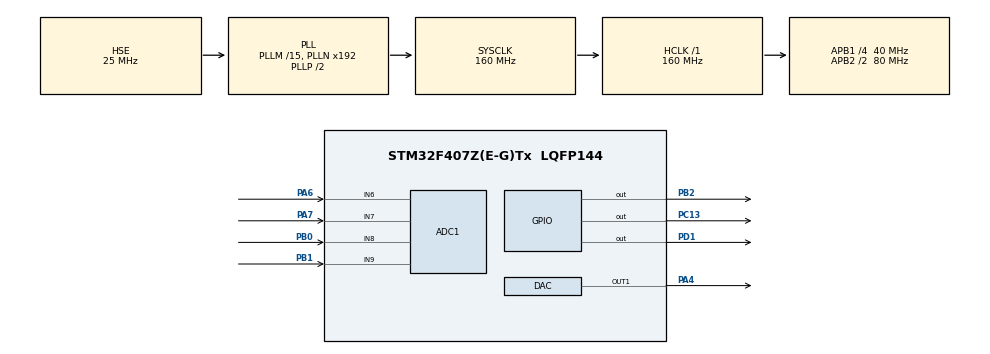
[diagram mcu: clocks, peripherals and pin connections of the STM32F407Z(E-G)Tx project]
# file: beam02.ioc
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ADC1.Channel-4\#ChannelRegularConversion=ADC_CHANNEL_6
ADC1.Channel-5\#ChannelRegularConversion=ADC_CHANNEL_7
ADC1.Channel-6\#ChannelRegularConversion=ADC_CHANNEL_8
ADC1.Channel-7\#ChannelRegularConversion=ADC_CHANNEL_9
ADC1.ContinuousConvMode=DISABLE
ADC1.DMAContinuousRequests=ENABLE
ADC1.EOCSelection=ADC_EOC_SEQ_CONV
ADC1.ExternalTrigConv=ADC_EXTERNALTRIGCONV_T8_TRGO
ADC1.NbrOfConversion=4
ADC1.NbrOfConversionFlag=1
ADC1.Rank-4\#ChannelRegularConversion=1
ADC1.Rank-5\#ChannelRegularConversion=2
ADC1.Rank-6\#ChannelRegularConversion=3
ADC1.Rank-7\#ChannelRegularConversion=4
ADC1.SamplingTime-4\#ChannelRegularConversion=ADC_SAMPLETIME_15CYCLES
ADC1.SamplingTime-5\#ChannelRegularConversion=ADC_SAMPLETIME_15CYCLES
ADC1.SamplingTime-6\#ChannelRegularConversion=ADC_SAMPLETIME_15CYCLES
ADC1.SamplingTime-7\#ChannelRegularConversion=ADC_SAMPLETIME_15CYCLES
ADC1.ScanConvMode=ENABLE
ADC1.master=1
Dma.ADC1.0.Direction=DMA_PERIPH_TO_MEMORY
Dma.ADC1.0.FIFOMode=DMA_FIFOMODE_DISABLE
Dma.ADC1.0.Instance=DMA2_Stream0
Dma.ADC1.0.MemDataAlignment=DMA_MDATAALIGN_WORD
Dma.ADC1.0.MemInc=DMA_MINC_ENABLE
Dma.ADC1.0.Mode=DMA_CIRCULAR
Dma.ADC1.0.PeriphDataAlignment=DMA_PDATAALIGN_WORD
Dma.ADC1.0.PeriphInc=DMA_PINC_DISABLE
Dma.ADC1.0.Priority=DMA_PRIORITY_LOW
Dma.DAC1.2.Direction=DMA_MEMORY_TO_PERIPH
Dma.DAC1.2.FIFOMode=DMA_FIFOMODE_DISABLE
Dma.DAC1.2.Instance=DMA1_Stream5
Dma.DAC1.2.MemDataAlignment=DMA_MDATAALIGN_WORD
Dma.DAC1.2.MemInc=DMA_MINC_ENABLE
Dma.DAC1.2.Mode=DMA_CIRCULAR
Dma.DAC1.2.PeriphDataAlignment=DMA_PDATAALIGN_WORD
Dma.DAC1.2.PeriphInc=DMA_PINC_DISABLE
Dma.DAC1.2.Priority=DMA_PRIORITY_LOW
Dma.Request0=ADC1
Dma.Request1=TIM6_UP
Dma.Request2=DAC1
Dma.TIM6_UP.1.Direction=DMA_PERIPH_TO_MEMORY
Dma.TIM6_UP.1.FIFOMode=DMA_FIFOMODE_DISABLE
Dma.TIM6_UP.1.Instance=DMA1_Stream1
Dma.TIM6_UP.1.MemDataAlignment=DMA_MDATAALIGN_WORD
Dma.TIM6_UP.1.MemInc=DMA_MINC_ENABLE
Dma.TIM6_UP.1.Mode=DMA_CIRCULAR
Dma.TIM6_UP.1.PeriphDataAlignment=DMA_PDATAALIGN_WORD
Dma.TIM6_UP.1.PeriphInc=DMA_PINC_DISABLE
Dma.TIM6_UP.1.Priority=DMA_PRIORITY_LOW
Mcu.Family=STM32F4
Mcu.Name=STM32F407Z(E-G)Tx
Mcu.Package=LQFP144
NVIC.ADC_IRQn=true\:0\:0\:false\:false\:true\:true\:true\:true
NVIC.DMA1_Stream1_IRQn=true\:0\:0\:false\:false\:true\:false\:true\:true
NVIC.DMA1_Stream5_IRQn=true\:0\:0\:false\:false\:true\:false\:true\:true
NVIC.DMA2_Stream0_IRQn=true\:0\:0\:false\:false\:true\:false\:true\:true
NVIC.PriorityGroup=NVIC_PRIORITYGROUP_4
NVIC.TIM6_DAC_IRQn=true\:0\:0\:false\:false\:true\:true\:true\:true
PA13.Mode=Trace_Asynchronous_SW
PA13.Signal=SYS_JTMS-SWDIO
PA14.Mode=Trace_Asynchronous_SW
PA14.Signal=SYS_JTCK-SWCLK
PA4.Signal=COMP_DAC1_group
PA6.Signal=ADCx_IN6
PA7.Signal=ADCx_IN7
PB0.Signal=ADCx_IN8
PB1.Signal=ADCx_IN9
PB2.Signal=GPIO_Output
PB3.Mode=Trace_Asynchronous_SW
PB3.Signal=SYS_JTDO-SWO
PC13-ANTI_TAMP.Signal=GPIO_Output
PD1.Signal=GPIO_Output
PH0-OSC_IN.Mode=HSE-External-Oscillator
PH0-OSC_IN.Signal=RCC_OSC_IN
PH1-OSC_OUT.Mode=HSE-External-Oscillator
PH1-OSC_OUT.Signal=RCC_OSC_OUT
ProjectManager.HeapSize=0x200
ProjectManager.StackSize=0x400
ProjectManager.TargetToolchain=STM32CubeIDE
RCC.48MHZClocksFreq_Value=80000000
RCC.AHBFreq_Value=160000000
RCC.APB1CLKDivider=RCC_HCLK_DIV4
RCC.APB1Freq_Value=40000000
RCC.APB1TimFreq_Value=80000000
RCC.APB2CLKDivider=RCC_HCLK_DIV2
RCC.APB2Freq_Value=80000000
RCC.APB2TimFreq_Value=160000000
RCC.CortexFreq_Value=160000000
RCC.HCLKFreq_Value=160000000
RCC.HSE_VALUE=25000000
RCC.HSI_VALUE=16000000
RCC.LSE_VALUE=32768
RCC.PLLM=15
RCC.PLLSourceVirtual=RCC_PLLSOURCE_HSE
RCC.SYSCLKFreq_VALUE=160000000
RCC.SYSCLKSource=RCC_SYSCLKSOURCE_PLLCLK
RCC.VCOOutputFreq_Value=320000000
SH.ADCx_IN6.0=ADC1_IN6,IN6
SH.ADCx_IN7.0=ADC1_IN7,IN7
SH.ADCx_IN8.0=ADC1_IN8,IN8
SH.ADCx_IN9.0=ADC1_IN9,IN9
SH.COMP_DAC1_group.0=DAC_OUT1,DAC_OUT1
TIM2.Channel-Output\ Compare1\ No\ Output=TIM_CHANNEL_1
TIM2.Channel-Output\ Compare3\ No\ Output=TIM_CHANNEL_3
TIM2.Channel-Output\ Compare4\ No\ Output=TIM_CHANNEL_4
TIM2.Channel-PWM\ Generation2\ No\ Output=TIM_CHANNEL_2
TIM6.Period=24
TIM6.Prescaler=19
TIM6.TIM_MasterOutputTrigger=TIM_TRGO_UPDATE
TIM8.AutoReloadPreload=TIM_AUTORELOAD_PRELOAD_DISABLE
TIM8.Period=24
TIM8.Prescaler=19
TIM8.RepetitionCounter=0
TIM8.TIM_MasterOutputTrigger=TIM_TRGO_UPDATE
VP_TIM1_VS_ClockSourceINT.Mode=Internal
VP_TIM2_VS_no_output1.Mode=Output Compare1 No Output
VP_TIM2_VS_no_output2.Mode=PWM Generation2 No Output
VP_TIM2_VS_no_output3.Mode=Output Compare3 No Output
VP_TIM2_VS_no_output4.Mode=Output Compare4 No Output
VP_TIM6_VS_ClockSourceINT.Mode=Enable_Timer
VP_TIM8_VS_ClockSourceINT.Mode=Internal
board=custom

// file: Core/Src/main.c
/* USER CODE BEGIN Header */
/**
  ******************************************************************************
  * @file           : main.c
  * @brief          : Main program body
  ******************************************************************************
  * @attention
  *
  * Copyright (c) 2025 STMicroelectronics.
  * All rights reserved.
  *
  * This software is licensed under terms that can be found in the LICENSE file
  * in the root directory of this software component.
  * If no LICENSE file comes with this software, it is provided AS-IS.
  *
  ******************************************************************************
  */
/* USER CODE END Header */
#include "main.h"

ADC_HandleTypeDef hadc1;
DMA_HandleTypeDef hdma_adc1;

DAC_HandleTypeDef hdac;
DMA_HandleTypeDef hdma_dac1;

TIM_HandleTypeDef htim1;
TIM_HandleTypeDef htim2;
TIM_HandleTypeDef htim6;
TIM_HandleTypeDef htim8;
DMA_HandleTypeDef hdma_tim6_up;

/* USER CODE BEGIN PV */

extern void pgm_loop();
extern void pgm_init();

long int acc = 33;

void HAL_ADC_ConvCpltCallback1(ADC_HandleTypeDef* hadc)
{
    // Conversion Complete & DMA Transfer Complete As Well
    // So The AD_RES_BUFFER Is Now Updated & Let's Move Values To The PWM CCRx
    // Update The PWM Channels With Latest ADC Scan Conversion Results
	/*
    TIM2->CCR1 = (AD_RES_BUFFER[0] << 4);  // ADC CH6 -> PWM CH1
    TIM2->CCR2 = (AD_RES_BUFFER[1] << 4);  // ADC CH7 -> PWM CH2
    TIM2->CCR3 = (AD_RES_BUFFER[2] << 4);  // ADC CH8 -> PWM CH3
    TIM2->CCR4 = (AD_RES_BUFFER[3] << 4);  // ADC CH9 -> PWM CH4
    */
    acc ++;
}

/* USER CODE END PV */

void SystemClock_Config(void);
static void MX_GPIO_Init(void);
static void MX_DMA_Init(void);
static void MX_ADC1_Init(void);
static void MX_TIM2_Init(void);
static void MX_DAC_Init(void);
static void MX_TIM6_Init(void);
static void MX_TIM8_Init(void);
static void MX_TIM1_Init(void);

int main(void)
{

  /* MCU Configuration--------------------------------------------------------*/

  /* Reset of all peripherals, Initializes the Flash interface and the Systick. */
  HAL_Init();

  /* Configure the system clock */
  SystemClock_Config();

  /* Initialize all configured peripherals */
  MX_GPIO_Init();
  MX_DMA_Init();
  MX_ADC1_Init();
  MX_TIM2_Init();
  MX_DAC_Init();
  MX_TIM6_Init();
  MX_TIM8_Init();
  MX_TIM1_Init();
  /* USER CODE BEGIN 2 */

  pgm_init();

  /* USER CODE END 2 */

  /* Infinite loop */
  /* USER CODE BEGIN WHILE */

  while (1)
  {
	  pgm_loop();
    /* USER CODE END WHILE */

  }
}

void SystemClock_Config(void)
{
  RCC_OscInitTypeDef RCC_OscInitStruct = {0};
  RCC_ClkInitTypeDef RCC_ClkInitStruct = {0};

  /** Configure the main internal regulator output voltage
  */
  __HAL_RCC_PWR_CLK_ENABLE();
  __HAL_PWR_VOLTAGESCALING_CONFIG(PWR_REGULATOR_VOLTAGE_SCALE1);

  /** Initializes the RCC Oscillators according to the specified parameters
  * in the RCC_OscInitTypeDef structure.
  */
  RCC_OscInitStruct.OscillatorType = RCC_OSCILLATORTYPE_HSE;
  RCC_OscInitStruct.HSEState = RCC_HSE_ON;
  RCC_OscInitStruct.PLL.PLLState = RCC_PLL_ON;
  RCC_OscInitStruct.PLL.PLLSource = RCC_PLLSOURCE_HSE;
  RCC_OscInitStruct.PLL.PLLM = 15;
  RCC_OscInitStruct.PLL.PLLN = 192;
  RCC_OscInitStruct.PLL.PLLP = RCC_PLLP_DIV2;
  RCC_OscInitStruct.PLL.PLLQ = 4;
  if (HAL_RCC_OscConfig(&RCC_OscInitStruct) != HAL_OK)
  {
    Error_Handler();
  }

  /** Initializes the CPU, AHB and APB buses clocks
  */
  RCC_ClkInitStruct.ClockType = RCC_CLOCKTYPE_HCLK|RCC_CLOCKTYPE_SYSCLK
                              |RCC_CLOCKTYPE_PCLK1|RCC_CLOCKTYPE_PCLK2;
  RCC_ClkInitStruct.SYSCLKSource = RCC_SYSCLKSOURCE_PLLCLK;
  RCC_ClkInitStruct.AHBCLKDivider = RCC_SYSCLK_DIV1;
  RCC_ClkInitStruct.APB1CLKDivider = RCC_HCLK_DIV4;
  RCC_ClkInitStruct.APB2CLKDivider = RCC_HCLK_DIV2;

  if (HAL_RCC_ClockConfig(&RCC_ClkInitStruct, FLASH_LATENCY_5) != HAL_OK)
  {
    Error_Handler();
  }
}

static void MX_ADC1_Init(void)
{

  ADC_ChannelConfTypeDef sConfig = {0};

  /** Configure the global features of the ADC (Clock, Resolution, Data Alignment and number of conversion)
  */
  hadc1.Instance = ADC1;
  hadc1.Init.ClockPrescaler = ADC_CLOCK_SYNC_PCLK_DIV4;
  hadc1.Init.Resolution = ADC_RESOLUTION_12B;
  hadc1.Init.ScanConvMode = ENABLE;
  hadc1.Init.ContinuousConvMode = DISABLE;
  hadc1.Init.DiscontinuousConvMode = DISABLE;
  hadc1.Init.ExternalTrigConvEdge = ADC_EXTERNALTRIGCONVEDGE_RISING;
  hadc1.Init.ExternalTrigConv = ADC_EXTERNALTRIGCONV_T8_TRGO;
  hadc1.Init.DataAlign = ADC_DATAALIGN_RIGHT;
  hadc1.Init.NbrOfConversion = 4;
  hadc1.Init.DMAContinuousRequests = ENABLE;
  hadc1.Init.EOCSelection = ADC_EOC_SEQ_CONV;
  if (HAL_ADC_Init(&hadc1) != HAL_OK)
  {
    Error_Handler();
  }

  /** Configure for the selected ADC regular channel its corresponding rank in the sequencer and its sample time.
  */
  sConfig.Channel = ADC_CHANNEL_6;
  sConfig.Rank = 1;
  sConfig.SamplingTime = ADC_SAMPLETIME_15CYCLES;
  if (HAL_ADC_ConfigChannel(&hadc1, &sConfig) != HAL_OK)
  {
    Error_Handler();
  }

  /** Configure for the selected ADC regular channel its corresponding rank in the sequencer and its sample time.
  */
  sConfig.Channel = ADC_CHANNEL_7;
  sConfig.Rank = 2;
  if (HAL_ADC_ConfigChannel(&hadc1, &sConfig) != HAL_OK)
  {
    Error_Handler();
  }

  /** Configure for the selected ADC regular channel its corresponding rank in the sequencer and its sample time.
  */
  sConfig.Channel = ADC_CHANNEL_8;
  sConfig.Rank = 3;
  if (HAL_ADC_ConfigChannel(&hadc1, &sConfig) != HAL_OK)
  {
    Error_Handler();
  }

  /** Configure for the selected ADC regular channel its corresponding rank in the sequencer and its sample time.
  */
  sConfig.Channel = ADC_CHANNEL_9;
  sConfig.Rank = 4;
  if (HAL_ADC_ConfigChannel(&hadc1, &sConfig) != HAL_OK)
  {
    Error_Handler();
  }

}

static void MX_DAC_Init(void)
{

  DAC_ChannelConfTypeDef sConfig = {0};

  /** DAC Initialization
  */
  hdac.Instance = DAC;
  if (HAL_DAC_Init(&hdac) != HAL_OK)
  {
    Error_Handler();
  }

  /** DAC channel OUT1 config
  */
  sConfig.DAC_Trigger = DAC_TRIGGER_NONE;
  sConfig.DAC_OutputBuffer = DAC_OUTPUTBUFFER_ENABLE;
  if (HAL_DAC_ConfigChannel(&hdac, &sConfig, DAC_CHANNEL_1) != HAL_OK)
  {
    Error_Handler();
  }

}

static void MX_TIM1_Init(void)
{

  TIM_ClockConfigTypeDef sClockSourceConfig = {0};
  TIM_MasterConfigTypeDef sMasterConfig = {0};

  htim1.Instance = TIM1;
  htim1.Init.Prescaler = 0;
  htim1.Init.CounterMode = TIM_COUNTERMODE_UP;
  htim1.Init.Period = 65535;
  htim1.Init.ClockDivision = TIM_CLOCKDIVISION_DIV1;
  htim1.Init.RepetitionCounter = 0;
  htim1.Init.AutoReloadPreload = TIM_AUTORELOAD_PRELOAD_DISABLE;
  if (HAL_TIM_Base_Init(&htim1) != HAL_OK)
  {
    Error_Handler();
  }
  sClockSourceConfig.ClockSource = TIM_CLOCKSOURCE_INTERNAL;
  if (HAL_TIM_ConfigClockSource(&htim1, &sClockSourceConfig) != HAL_OK)
  {
    Error_Handler();
  }
  sMasterConfig.MasterOutputTrigger = TIM_TRGO_RESET;
  sMasterConfig.MasterSlaveMode = TIM_MASTERSLAVEMODE_DISABLE;
  if (HAL_TIMEx_MasterConfigSynchronization(&htim1, &sMasterConfig) != HAL_OK)
  {
    Error_Handler();
  }

}

static void MX_TIM2_Init(void)
{

  TIM_MasterConfigTypeDef sMasterConfig = {0};
  TIM_OC_InitTypeDef sConfigOC = {0};

  htim2.Instance = TIM2;
  htim2.Init.Prescaler = 0;
  htim2.Init.CounterMode = TIM_COUNTERMODE_UP;
  htim2.Init.Period = 4294967295;
  htim2.Init.ClockDivision = TIM_CLOCKDIVISION_DIV1;
  htim2.Init.AutoReloadPreload = TIM_AUTORELOAD_PRELOAD_DISABLE;
  if (HAL_TIM_OC_Init(&htim2) != HAL_OK)
  {
    Error_Handler();
  }
  if (HAL_TIM_PWM_Init(&htim2) != HAL_OK)
  {
    Error_Handler();
  }
  sMasterConfig.MasterOutputTrigger = TIM_TRGO_RESET;
  sMasterConfig.MasterSlaveMode = TIM_MASTERSLAVEMODE_DISABLE;
  if (HAL_TIMEx_MasterConfigSynchronization(&htim2, &sMasterConfig) != HAL_OK)
  {
    Error_Handler();
  }
  sConfigOC.OCMode = TIM_OCMODE_TIMING;
  sConfigOC.Pulse = 0;
  sConfigOC.OCPolarity = TIM_OCPOLARITY_HIGH;
  sConfigOC.OCFastMode = TIM_OCFAST_DISABLE;
  if (HAL_TIM_OC_ConfigChannel(&htim2, &sConfigOC, TIM_CHANNEL_1) != HAL_OK)
  {
    Error_Handler();
  }
  sConfigOC.OCMode = TIM_OCMODE_PWM1;
  if (HAL_TIM_PWM_ConfigChannel(&htim2, &sConfigOC, TIM_CHANNEL_2) != HAL_OK)
  {
    Error_Handler();
  }
  sConfigOC.OCMode = TIM_OCMODE_TIMING;
  if (HAL_TIM_OC_ConfigChannel(&htim2, &sConfigOC, TIM_CHANNEL_3) != HAL_OK)
  {
    Error_Handler();
  }
  if (HAL_TIM_OC_ConfigChannel(&htim2, &sConfigOC, TIM_CHANNEL_4) != HAL_OK)
  {
    Error_Handler();
  }

}

static void MX_TIM6_Init(void)
{

  TIM_MasterConfigTypeDef sMasterConfig = {0};

  htim6.Instance = TIM6;
  htim6.Init.Prescaler = 19;
  htim6.Init.CounterMode = TIM_COUNTERMODE_UP;
  htim6.Init.Period = 24;
  htim6.Init.AutoReloadPreload = TIM_AUTORELOAD_PRELOAD_DISABLE;
  if (HAL_TIM_Base_Init(&htim6) != HAL_OK)
  {
    Error_Handler();
  }
  sMasterConfig.MasterOutputTrigger = TIM_TRGO_UPDATE;
  sMasterConfig.MasterSlaveMode = TIM_MASTERSLAVEMODE_DISABLE;
  if (HAL_TIMEx_MasterConfigSynchronization(&htim6, &sMasterConfig) != HAL_OK)
  {
    Error_Handler();
  }

}

static void MX_TIM8_Init(void)
{

  TIM_ClockConfigTypeDef sClockSourceConfig = {0};
  TIM_MasterConfigTypeDef sMasterConfig = {0};

  htim8.Instance = TIM8;
  htim8.Init.Prescaler = 19;
  htim8.Init.CounterMode = TIM_COUNTERMODE_UP;
  htim8.Init.Period = 24;
  htim8.Init.ClockDivision = TIM_CLOCKDIVISION_DIV1;
  htim8.Init.RepetitionCounter = 0;
  htim8.Init.AutoReloadPreload = TIM_AUTORELOAD_PRELOAD_DISABLE;
  if (HAL_TIM_Base_Init(&htim8) != HAL_OK)
  {
    Error_Handler();
  }
  sClockSourceConfig.ClockSource = TIM_CLOCKSOURCE_INTERNAL;
  if (HAL_TIM_ConfigClockSource(&htim8, &sClockSourceConfig) != HAL_OK)
  {
    Error_Handler();
  }
  sMasterConfig.MasterOutputTrigger = TIM_TRGO_UPDATE;
  sMasterConfig.MasterSlaveMode = TIM_MASTERSLAVEMODE_DISABLE;
  if (HAL_TIMEx_MasterConfigSynchronization(&htim8, &sMasterConfig) != HAL_OK)
  {
    Error_Handler();
  }

}

static void MX_DMA_Init(void)
{

  /* DMA controller clock enable */
  __HAL_RCC_DMA2_CLK_ENABLE();
  __HAL_RCC_DMA1_CLK_ENABLE();

  /* DMA interrupt init */
  /* DMA1_Stream1_IRQn interrupt configuration */
  HAL_NVIC_SetPriority(DMA1_Stream1_IRQn, 0, 0);
  HAL_NVIC_EnableIRQ(DMA1_Stream1_IRQn);
  /* DMA1_Stream5_IRQn interrupt configuration */
  HAL_NVIC_SetPriority(DMA1_Stream5_IRQn, 0, 0);
  HAL_NVIC_EnableIRQ(DMA1_Stream5_IRQn);
  /* DMA2_Stream0_IRQn interrupt configuration */
  HAL_NVIC_SetPriority(DMA2_Stream0_IRQn, 0, 0);
  HAL_NVIC_EnableIRQ(DMA2_Stream0_IRQn);

}

static void MX_GPIO_Init(void)
{
  GPIO_InitTypeDef GPIO_InitStruct = {0};

  /* GPIO Ports Clock Enable */
  __HAL_RCC_GPIOC_CLK_ENABLE();
  __HAL_RCC_GPIOH_CLK_ENABLE();
  __HAL_RCC_GPIOA_CLK_ENABLE();
  __HAL_RCC_GPIOB_CLK_ENABLE();
  __HAL_RCC_GPIOD_CLK_ENABLE();

  /*Configure GPIO pin Output Level */
  HAL_GPIO_WritePin(GPIOC, GPIO_PIN_13, GPIO_PIN_RESET);

  /*Configure GPIO pin Output Level */
  HAL_GPIO_WritePin(GPIOB, GPIO_PIN_2, GPIO_PIN_RESET);

  /*Configure GPIO pin Output Level */
  HAL_GPIO_WritePin(GPIOD, GPIO_PIN_1, GPIO_PIN_RESET);

  /*Configure GPIO pin : PC13 */
  GPIO_InitStruct.Pin = GPIO_PIN_13;
  GPIO_InitStruct.Mode = GPIO_MODE_OUTPUT_PP;
  GPIO_InitStruct.Pull = GPIO_NOPULL;
  GPIO_InitStruct.Speed = GPIO_SPEED_FREQ_LOW;
  HAL_GPIO_Init(GPIOC, &GPIO_InitStruct);

  /*Configure GPIO pin : PB2 */
  GPIO_InitStruct.Pin = GPIO_PIN_2;
  GPIO_InitStruct.Mode = GPIO_MODE_OUTPUT_PP;
  GPIO_InitStruct.Pull = GPIO_NOPULL;
  GPIO_InitStruct.Speed = GPIO_SPEED_FREQ_LOW;
  HAL_GPIO_Init(GPIOB, &GPIO_InitStruct);

  /*Configure GPIO pin : PD1 */
  GPIO_InitStruct.Pin = GPIO_PIN_1;
  GPIO_InitStruct.Mode = GPIO_MODE_OUTPUT_PP;
  GPIO_InitStruct.Pull = GPIO_NOPULL;
  GPIO_InitStruct.Speed = GPIO_SPEED_FREQ_LOW;
  HAL_GPIO_Init(GPIOD, &GPIO_InitStruct);

}

void Error_Handler(void)
{
  __disable_irq();
  while (1)
  {
  }
}
